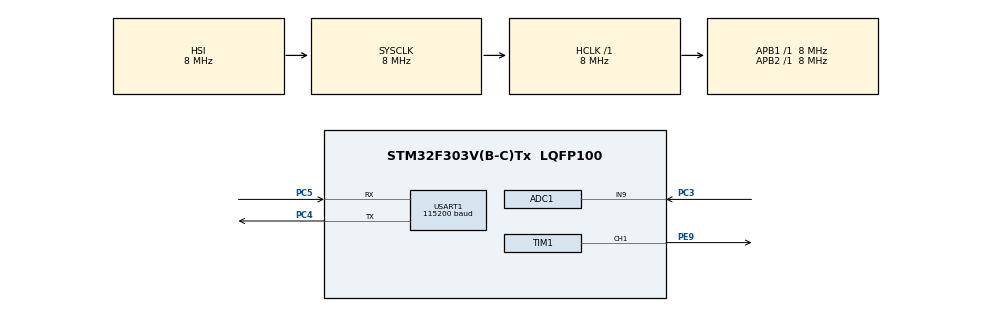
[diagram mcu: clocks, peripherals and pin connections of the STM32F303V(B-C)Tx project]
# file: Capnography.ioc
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ADC1.Channel-0\#ChannelRegularConversion=ADC_CHANNEL_9
ADC1.NbrOfConversionFlag=1
ADC1.Offset-0\#ChannelRegularConversion=0
ADC1.OffsetNumber-0\#ChannelRegularConversion=ADC_OFFSET_NONE
ADC1.Rank-0\#ChannelRegularConversion=1
ADC1.SamplingTime-0\#ChannelRegularConversion=ADC_SAMPLETIME_1CYCLE_5
ADC1.SamplingTimeOPAMP-0\#ChannelRegularConversion=ADC_SAMPLETIME_4CYCLES_5
ADC1.master=1
Mcu.Family=STM32F3
Mcu.Name=STM32F303V(B-C)Tx
Mcu.Package=LQFP100
NVIC.PriorityGroup=NVIC_PRIORITYGROUP_4
PC3.Signal=ADCx_IN9
PC4.Mode=Asynchronous
PC4.Signal=USART1_TX
PC5.Mode=Asynchronous
PC5.Signal=USART1_RX
PE9.Signal=S_TIM1_CH1
ProjectManager.HeapSize=0x200
ProjectManager.StackSize=0x400
ProjectManager.TargetToolchain=STM32CubeIDE
RCC.AHBFreq_Value=8000000
RCC.APB1Freq_Value=8000000
RCC.APB2Freq_Value=8000000
RCC.CortexFreq_Value=8000000
RCC.HSE_VALUE=8000000
RCC.HSI_VALUE=8000000
RCC.LSE_VALUE=32768
RCC.SYSCLKFreq_VALUE=8000000
SH.ADCx_IN9.0=ADC1_IN9,IN9-Single-Ended
SH.S_TIM1_CH1.0=TIM1_CH1,PWM Generation1 CH1
TIM1.Channel-PWM\ Generation1\ CH1=TIM_CHANNEL_1
USART1.BaudRate=115200
USART1.VirtualMode-Asynchronous=VM_ASYNC
board=custom

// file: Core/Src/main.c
/* USER CODE BEGIN Header */
/**
  ******************************************************************************
  * @file           : main.c
  * @brief          : Main program body
  ******************************************************************************
  * @attention
  *
  * Copyright (c) 2024 STMicroelectronics.
  * All rights reserved.
  *
  * This software is licensed under terms that can be found in the LICENSE file
  * in the root directory of this software component.
  * If no LICENSE file comes with this software, it is provided AS-IS.
  *
  ******************************************************************************
  */
/* USER CODE END Header */
#include "main.h"
#include <stdio.h>

ADC_HandleTypeDef hadc1;

TIM_HandleTypeDef htim1;

UART_HandleTypeDef huart1;

void SystemClock_Config(void);
static void MX_GPIO_Init(void);
static void MX_TIM1_Init(void);
static void MX_ADC1_Init(void);
static void MX_USART1_UART_Init(void);
static uint32_t ADC_GetValueInMillivolts(void);

int main(void)
{

  /* MCU Configuration--------------------------------------------------------*/

  /* Reset of all peripherals, Initializes the Flash interface and the Systick. */
  HAL_Init();

  /* Configure the system clock */
  SystemClock_Config();

  /* Initialize all configured peripherals */
  MX_GPIO_Init();
  MX_TIM1_Init();
  MX_ADC1_Init();
  MX_USART1_UART_Init();
  /* USER CODE BEGIN 2 */

  /*To start the PWM signal*/
  HAL_TIM_PWM_Start(&htim1, TIM_CHANNEL_1);

  // Calibrate the ADC before use
  HAL_ADCEx_Calibration_Start(&hadc1, ADC_SINGLE_ENDED);

  // Start ADC in continuous conversion mode
  HAL_ADC_Start(&hadc1);

  /* USER CODE END 2 */

  /* Infinite loop */
  /* USER CODE BEGIN WHILE */
  while (1)
  {
	int adcMillivolts = ADC_GetValueInMillivolts();
	printf("%d,\r\n", adcMillivolts);
	//HAL_Delay(100);
    /* USER CODE END WHILE */

  }
}

void SystemClock_Config(void)
{
  RCC_OscInitTypeDef RCC_OscInitStruct = {0};
  RCC_ClkInitTypeDef RCC_ClkInitStruct = {0};
  RCC_PeriphCLKInitTypeDef PeriphClkInit = {0};

  /** Initializes the RCC Oscillators according to the specified parameters
  * in the RCC_OscInitTypeDef structure.
  */
  RCC_OscInitStruct.OscillatorType = RCC_OSCILLATORTYPE_HSI;
  RCC_OscInitStruct.HSIState = RCC_HSI_ON;
  RCC_OscInitStruct.HSICalibrationValue = RCC_HSICALIBRATION_DEFAULT;
  RCC_OscInitStruct.PLL.PLLState = RCC_PLL_ON;
  RCC_OscInitStruct.PLL.PLLSource = RCC_PLLSOURCE_HSI;
  RCC_OscInitStruct.PLL.PLLMUL = RCC_PLL_MUL2;
  if (HAL_RCC_OscConfig(&RCC_OscInitStruct) != HAL_OK)
  {
    Error_Handler();
  }

  /** Initializes the CPU, AHB and APB buses clocks
  */
  RCC_ClkInitStruct.ClockType = RCC_CLOCKTYPE_HCLK|RCC_CLOCKTYPE_SYSCLK
                              |RCC_CLOCKTYPE_PCLK1|RCC_CLOCKTYPE_PCLK2;
  RCC_ClkInitStruct.SYSCLKSource = RCC_SYSCLKSOURCE_HSI;
  RCC_ClkInitStruct.AHBCLKDivider = RCC_SYSCLK_DIV1;
  RCC_ClkInitStruct.APB1CLKDivider = RCC_HCLK_DIV1;
  RCC_ClkInitStruct.APB2CLKDivider = RCC_HCLK_DIV1;

  if (HAL_RCC_ClockConfig(&RCC_ClkInitStruct, FLASH_LATENCY_0) != HAL_OK)
  {
    Error_Handler();
  }
  PeriphClkInit.PeriphClockSelection = RCC_PERIPHCLK_USART1|RCC_PERIPHCLK_TIM1
                              |RCC_PERIPHCLK_ADC12;
  PeriphClkInit.Usart1ClockSelection = RCC_USART1CLKSOURCE_PCLK2;
  PeriphClkInit.Adc12ClockSelection = RCC_ADC12PLLCLK_DIV1;
  PeriphClkInit.Tim1ClockSelection = RCC_TIM1CLK_HCLK;
  if (HAL_RCCEx_PeriphCLKConfig(&PeriphClkInit) != HAL_OK)
  {
    Error_Handler();
  }
}

static void MX_ADC1_Init(void)
{

  ADC_MultiModeTypeDef multimode = {0};
  ADC_ChannelConfTypeDef sConfig = {0};

  /** Common config
  */
  hadc1.Instance = ADC1;
  hadc1.Init.ClockPrescaler = ADC_CLOCK_ASYNC_DIV1;
  hadc1.Init.Resolution = ADC_RESOLUTION_12B;
  hadc1.Init.ScanConvMode = ADC_SCAN_DISABLE;
  hadc1.Init.ContinuousConvMode = ENABLE;
  hadc1.Init.DiscontinuousConvMode = DISABLE;
  hadc1.Init.ExternalTrigConvEdge = ADC_EXTERNALTRIGCONVEDGE_NONE;
  hadc1.Init.ExternalTrigConv = ADC_SOFTWARE_START;
  hadc1.Init.DataAlign = ADC_DATAALIGN_RIGHT;
  hadc1.Init.NbrOfConversion = 1;
  hadc1.Init.DMAContinuousRequests = DISABLE;
  hadc1.Init.EOCSelection = ADC_EOC_SINGLE_CONV;
  hadc1.Init.LowPowerAutoWait = DISABLE;
  hadc1.Init.Overrun = ADC_OVR_DATA_OVERWRITTEN;
  if (HAL_ADC_Init(&hadc1) != HAL_OK)
  {
    Error_Handler();
  }

  /** Configure the ADC multi-mode
  */
  multimode.Mode = ADC_MODE_INDEPENDENT;
  if (HAL_ADCEx_MultiModeConfigChannel(&hadc1, &multimode) != HAL_OK)
  {
    Error_Handler();
  }

  /** Configure Regular Channel
  */
  sConfig.Channel = ADC_CHANNEL_9;
  sConfig.Rank = ADC_REGULAR_RANK_1;
  sConfig.SingleDiff = ADC_SINGLE_ENDED;
  sConfig.SamplingTime = ADC_SAMPLETIME_1CYCLE_5;
  sConfig.OffsetNumber = ADC_OFFSET_NONE;
  sConfig.Offset = 0;
  if (HAL_ADC_ConfigChannel(&hadc1, &sConfig) != HAL_OK)
  {
    Error_Handler();
  }

}

static void MX_TIM1_Init(void)
{

  TIM_MasterConfigTypeDef sMasterConfig = {0};
  TIM_OC_InitTypeDef sConfigOC = {0};
  TIM_BreakDeadTimeConfigTypeDef sBreakDeadTimeConfig = {0};

  htim1.Instance = TIM1;
  htim1.Init.Prescaler = 2;
  htim1.Init.CounterMode = TIM_COUNTERMODE_UP;
  htim1.Init.Period = 80;
  htim1.Init.ClockDivision = TIM_CLOCKDIVISION_DIV1;
  htim1.Init.RepetitionCounter = 0;
  htim1.Init.AutoReloadPreload = TIM_AUTORELOAD_PRELOAD_DISABLE;
  if (HAL_TIM_PWM_Init(&htim1) != HAL_OK)
  {
    Error_Handler();
  }
  sMasterConfig.MasterOutputTrigger = TIM_TRGO_RESET;
  sMasterConfig.MasterOutputTrigger2 = TIM_TRGO2_RESET;
  sMasterConfig.MasterSlaveMode = TIM_MASTERSLAVEMODE_DISABLE;
  if (HAL_TIMEx_MasterConfigSynchronization(&htim1, &sMasterConfig) != HAL_OK)
  {
    Error_Handler();
  }
  sConfigOC.OCMode = TIM_OCMODE_PWM1;
  sConfigOC.Pulse = 499;
  sConfigOC.OCPolarity = TIM_OCPOLARITY_HIGH;
  sConfigOC.OCNPolarity = TIM_OCNPOLARITY_HIGH;
  sConfigOC.OCFastMode = TIM_OCFAST_DISABLE;
  sConfigOC.OCIdleState = TIM_OCIDLESTATE_RESET;
  sConfigOC.OCNIdleState = TIM_OCNIDLESTATE_RESET;
  if (HAL_TIM_PWM_ConfigChannel(&htim1, &sConfigOC, TIM_CHANNEL_1) != HAL_OK)
  {
    Error_Handler();
  }
  sBreakDeadTimeConfig.OffStateRunMode = TIM_OSSR_DISABLE;
  sBreakDeadTimeConfig.OffStateIDLEMode = TIM_OSSI_DISABLE;
  sBreakDeadTimeConfig.LockLevel = TIM_LOCKLEVEL_OFF;
  sBreakDeadTimeConfig.DeadTime = 0;
  sBreakDeadTimeConfig.BreakState = TIM_BREAK_DISABLE;
  sBreakDeadTimeConfig.BreakPolarity = TIM_BREAKPOLARITY_HIGH;
  sBreakDeadTimeConfig.BreakFilter = 0;
  sBreakDeadTimeConfig.Break2State = TIM_BREAK2_DISABLE;
  sBreakDeadTimeConfig.Break2Polarity = TIM_BREAK2POLARITY_HIGH;
  sBreakDeadTimeConfig.Break2Filter = 0;
  sBreakDeadTimeConfig.AutomaticOutput = TIM_AUTOMATICOUTPUT_DISABLE;
  if (HAL_TIMEx_ConfigBreakDeadTime(&htim1, &sBreakDeadTimeConfig) != HAL_OK)
  {
    Error_Handler();
  }
  HAL_TIM_MspPostInit(&htim1);

}

static void MX_USART1_UART_Init(void)
{

  huart1.Instance = USART1;
  huart1.Init.BaudRate = 115200;
  huart1.Init.WordLength = UART_WORDLENGTH_8B;
  huart1.Init.StopBits = UART_STOPBITS_1;
  huart1.Init.Parity = UART_PARITY_NONE;
  huart1.Init.Mode = UART_MODE_TX_RX;
  huart1.Init.HwFlowCtl = UART_HWCONTROL_NONE;
  huart1.Init.OverSampling = UART_OVERSAMPLING_16;
  huart1.Init.OneBitSampling = UART_ONE_BIT_SAMPLE_DISABLE;
  huart1.AdvancedInit.AdvFeatureInit = UART_ADVFEATURE_NO_INIT;
  if (HAL_UART_Init(&huart1) != HAL_OK)
  {
    Error_Handler();
  }

}

static uint32_t ADC_GetValueInMillivolts(void) {
	// Poll ADC for conversion
	if (HAL_ADC_PollForConversion(&hadc1, HAL_MAX_DELAY) == HAL_OK) {
		uint32_t adcValue = HAL_ADC_GetValue(&hadc1);
		// Convert ADC value to millivolts
		uint32_t adcMillivolts = (adcValue * 3000) / 4095; // Assuming Vref = 3.3V and 12-bit ADC
		return adcMillivolts;
	}
	return 0;
}

int _write(int file, char *data, int len) {
	HAL_UART_Transmit(&huart1, (uint8_t*) data, len, HAL_MAX_DELAY);
	return len;
}

static void MX_GPIO_Init(void)
{

  /* GPIO Ports Clock Enable */
  __HAL_RCC_GPIOC_CLK_ENABLE();
  __HAL_RCC_GPIOE_CLK_ENABLE();

}

void Error_Handler(void)
{
  __disable_irq();
  while (1)
  {
  }
}
